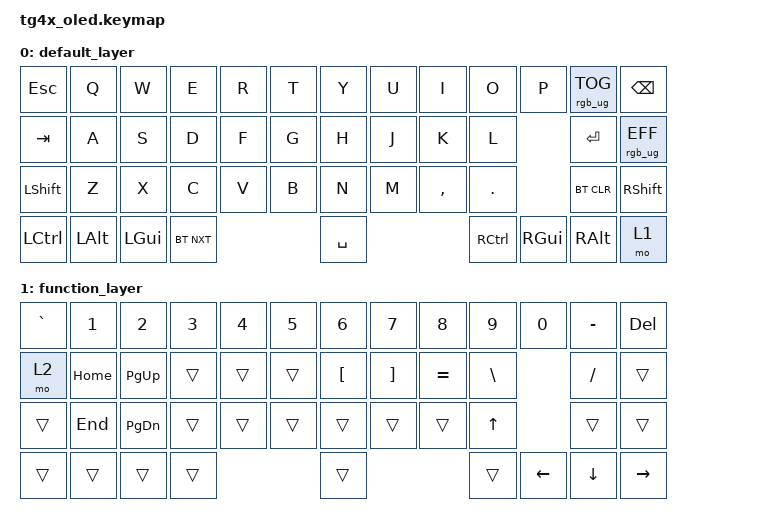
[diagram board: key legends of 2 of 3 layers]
/*
 * Copyright (c) 2020 The ZMK Contributors
 *
 * SPDX-License-Identifier: MIT
 */

#include <behaviors.dtsi>
#include <dt-bindings/zmk/keys.h>
#include <dt-bindings/zmk/bt.h>
#include <dt-bindings/zmk/rgb.h>

/ {
	behaviors {
		ht: hold_tap {
			compatible = "zmk,behavior-hold-tap";
			label = "Hold Tap";
			#binding-cells = <2>;
			tapping-term-ms = <200>;
			flavor = "tap-preferred";
			bindings = <&kp>, <&kp>;
		};
	};

	keymap {
		compatible = "zmk,keymap";

		default_layer {

// ----------------------------------------------------------------------------------------------------------------------------------
// |   ESC   |    Q    |    W    |    E    |    R    |    T    |    Y    |    U    |    I    |    O    |    P    |    #   |   BCKS  |
// |   TAB   |    A    |    S    |    D    |    F    |    G    |    H    |    J    |    K    |    L    |       ENTER      |    #    |
// |  SHIFT  |    Z    |    X    |    C    |    V    |    B    |    N    |    M    |    ,    |    .    |    #    |      SHIFT       |
// |  L CTRL |  L OPT  |  L CMD  |    #    |                           SPACE                           |  R CMD  |  R OPT |    FN   |

			bindings = <
&kp ESC      &kp Q    &kp W    &kp E       &kp R &kp T &kp Y &kp U &kp I     &kp O     &kp P    &rgb_ug RGB_TOG &kp BSPC
&kp TAB      &kp A    &kp S    &kp D       &kp F &kp G &kp H &kp J &kp K     &kp L    	        &kp RET  		&rgb_ug RGB_EFF
&kp LSHFT    &kp Z    &kp X    &kp C       &kp V &kp B &kp N &kp M &kp COMMA &kp DOT            &bt BT_CLR      &kp RSHFT
&kp LCTRL    &kp LALT &kp LGUI &bt BT_NXT            &kp SPACE     			 &kp RCTRL &kp RGUI &kp RALT        &mo 1
			>;
		};

		function_layer {
			bindings = <
&kp GRAVE &kp N1   &kp N2    &kp N3 &kp N4 &kp N5 &kp N6   &kp N7   &kp N8    &kp N9    &kp N0   &kp MINUS &kp DEL
&mo 2     &kp HOME &kp PG_UP &trans &trans &trans &kp LBKT &kp RBKT &kp EQUAL &kp BSLH  &kp FSLH           &trans
&trans    &kp END  &kp PG_DN &trans &trans &trans &trans   &trans   &trans    &kp UP    &trans             &trans
&trans    &trans   &trans    &trans                        &trans   &trans    &kp LEFT  &kp DOWN           &kp RIGHT
			>;
		};

		other_layer {
			bindings = <
&kp PRINTSCREEN &kp F1     &kp F2     &kp F3     &kp F4 &kp F5 &kp F6 &kp F7 &kp F8       &kp F9       &kp F10  &kp F11 &kp F12
&trans          &trans     &trans     &trans     &trans &trans &trans &trans &trans       &trans       &trans           &trans
&trans          &bt BT_CLR &bt BT_PRV &bt BT_NXT &trans &trans &trans &trans &bootloader  &reset       &trans           &trans
&trans          &trans     &trans     &trans                          &trans &kp C_VOL_UP &kp C_VOL_DN                  &kp C_PP
			>;
		};

	};
};
